# PIC32CX2051BZ62132 device description
Architecture: CORTEX-M4; Family: PIC32CX; Series: PIC32CXBZ62
Registers are 32-bit, read-write, reset 0x0 unless marked. A register's access mark holds for its fields unless they carry their own. Offsets are from the block's base; [hi:lo] are bit positions; 'fields as' and 'values as' point back to an identical list.

## QEI
Instances: QEI 0x44005000
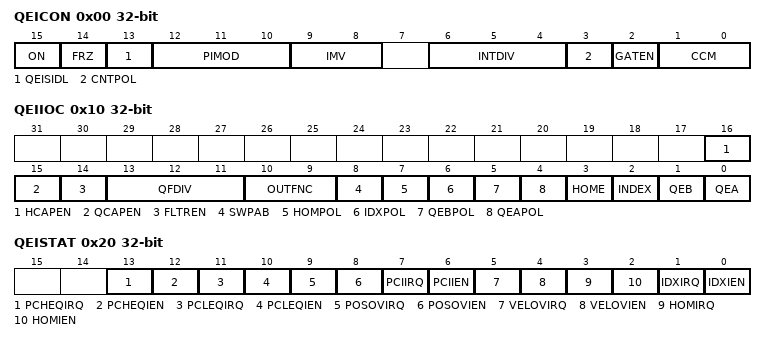
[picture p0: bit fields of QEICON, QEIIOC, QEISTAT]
0x00 QEICON reset not defined — QEI Control Register
  [15] ON — Quadrature Encoder Interface Module Counter Enable bit
    1=ON (Module counters are enabled); 0=OFF (Module counters are disabled)
  [14] FRZ — Quadrature Encoder Interface Freeze debug mode
  [13] QEISIDL — Stop in Idle Mode bit
    1=DISCONT (Discontinue module operation when device enters Idle mode); 0=CONT (Continue module operation in Idle mode)
  [12:10] PIMOD — Position Counter Initialization Mode Select bits
    7=Modulo Count mode for position counter and every index event resets the position counter; 6=Modulo Count mode for position counter; 5=Resets the position counter when the position counter equals QEIICCH register; 4=Second index event after home event initializes position counter with contents of QEIICCHregister; 3=First index event after home event initializes position counter with contents of QEIICCH register; 2=Next index input event initializes the position counter with contents of QEIICCH register; 1=Every Index input event resets the position counter; 0=Index input event does not affect position counter
  [9:8] IMV — Index Match Value bits
    3=B1_A1 (Index match occurs when QEB is 1 and QEA is 1); 2=B1_A0 (Index match occurs when QEB is 1 and QEA is 0); 1=B0_A1 (Index match occurs when QEB is 0 and QEA is 1); 0=B0_A0 (Index match occurs when QEB is 0 and QEA is 0)
  [6:4] INTDIV — Timer Input Clock Prescale Select bits
    7=1:128 prescale value; 6=1:64 prescale value; 5=1:32 prescale value; 4=1:16 prescale value; 3=1_8 (1:8 prescale value); 2=1_4 (1:4 prescale value); 1=1_2 (1:2 prescale value); 0=1:1 prescale value
  [3] CNTPOL — Position and Index Counter/Timer Direction Select bit
    1=NEG (Counter direction is negative unless modified by external Up/Down signal); 0=POS (Counter direction is positive unless modified by external Up/Down signal)
  [2] GATEN — External Count Gate Enable bit
    1=ON (External gate signal controls position counter operation); 0=OFF (External gate signal has no affect on position counter/timer operation)
  [1:0] CCM — Counter Control Mode Selection bits
    3=INT_TMR_EXT_COUNT (Internal timer mode with optional external count enable); 2=EXT_CLOCK_EXT_COUNT (External clock count with optional external count gating); 1=EXT_CLK_EXT_UPDN (External clock count with external Up/Dn direction selection); 0=COUNT_MODE (Quadrature Encoder Interface Count mode (x4 mode))
0x04 QEICONCLR — Bit clear register
0x08 QEICONSET — Bit set register
0x0C QEICONINV — Bit invert register
0x10 QEIIOC reset not defined — QEI I/O Control Register
  [16] HCAPEN — Position Counter Input Capture by Home Event Enable bit
    1=TRIGGERED (HOMEx input event (positive edge) triggers a position capture event); 0=NOT_TRIGGERED (HOMEx input event (positive edge) does not trigger a position capture event)
  [15] QCAPEN — Position Counter Input Capture Enable bit
    1=TRIGGERED (Positive edge detect of Home input triggers position capture function); 0=NOT_TRIGGERED (Home input event (positive edge) does not trigger a capture even)
  [14] FLTREN — QEA/QEB/INDX/HOMEx Digital Filter Enable bit
    1=ON (Input Pin Digital filter is enabled); 0=OFF (Input Pin Digital filter is disabled (bypassed))
  [13:11] QFDIV — QEA/QEB/INDX/HOMEx Digital Input Filter Clock Divide Select bits
    7=1:128 clock divide; 6=1:64 clock divide; 5=1:32 clock divide; 4=1:16 clock divide; 3=1_8 (1:8 clock divide); 2=1_4 (1:4 clock divide); 1=1_2 (1:2 clock divide); 0=1:1 clock divide
  [10:9] OUTFNC — QEI Module Output Function Mode Select bits
    3=EITHER (The position coutner is either case); 2=LESS_THAN (The position counter less than or equal to the range of CMPLH and CMPLL); 1=GREATER_THAN (The position counter greater than or equal to the range of ICCH and ICCL); 0=DISABLE (Output is disabled)
  [8] SWPAB — Swap QEA and QEB Inputs bit
    1=SWAP (QEAx and QEBx are swapped prior to quadrature decoder logic); 0=NORMAL (QEAx and QEBx are not swapped)
  [7] HOMPOL — HOMEx Input Polarity Select bit
    1=INVERT (Input is inverted); 0=NORMAL (Input is not inverted)
  [6] IDXPOL — INDXx Input Polarity Select bit
    values as HOMPOL
  [5] QEBPOL — QEBx Input Polarity Select bit
    values as HOMPOL
  [4] QEAPOL — QEAx Input Polarity Select bit
    values as HOMPOL
  [3] HOME — Status of HOMEx Input Pin after Polarity Control bit
  [2] INDEX — Status of INDXx Input Pin after Polarity Control bit
  [1] QEB — Status of QEBx Input Pin after Polarity Control and SWPAB Pin Swapping bit
    1=Status of QEB input pin after polarity control and SWPAB pin swapping; 0=Status of QEB input pin after polarity control and SWPAB pin swapping
  [0] QEA — Status of QEAx Input Pin after Polarity Control and SWPAB Pin Swapping bit
    1=Status of QEA input pin after polarity control and SWPAB pin swapping; 0=Status of QEA input pin after polarity control and SWPAB pin swapping
0x14 QQEIIOCCLR — Bit clear register
0x18 QEIIOCSET — Bit set register
0x1C QEIIOCINV — Bit invert register
0x20 QEISTAT reset not defined — QEI Status Register
  [13] PCHEQIRQ — Position Counter Greater Than or Equal Compare Status bit
    1=MORE_EQUAL (POSxCNT greater than or equal to QEIICCH); 0=LESS (POSxCNT less than QEIICCH)
  [12] PCHEQIEN — Position Counter Greater Than or Equal Compare Interrupt Enable bit
    1=ON (Interrupt is enabled); 0=OFF (Interrupt is disabled)
  [11] PCLEQIRQ — Position Counter Less Than or Equal Compare Status bit
    1=LESS_EQUAL (POSxCNT less than or equal to QEICMPL); 0=GREATER (POSxCNT greater than QEICMPL)
  [10] PCLEQIEN — Position Counter Less Than or Equal Compare Interrupt Enable bit
    1=ON (Interrupt is enabled); 0=OFF (Interrupt is disabled)
  [9] POSOVIRQ — Position Counter Overflow Status bit
    1=OVERFLOW (Overflow has occurred); 0=NO_OVERFLOW (No overflow has occurred)
  [8] POSOVIEN — Position Counter Overflow Interrupt Enable bit
    1=ON (Interrupt is enabled); 0=OFF (Interrupt is disabled)
  [7] PCIIRQ — Position Counter Initialization Process Complete Status bit
    1=DONE (POSxCNT was reinitialized); 0=NOT_DONE (POSxCNT was not reinitialized)
  [6] PCIIEN — Position Counter Initialization Process Complete Interrupt Enable bit
    1=ON (Interrupt is enabled); 0=OFF (Interrupt is disabled)
  [5] VELOVIRQ — Velocity Counter Overflow Status bit
    1=OVERFLOW (Overflow has occurred); 0=NO_OVERFLOW (No overflow has not occurred)
  [4] VELOVIEN — Velocity Counter Overflow Interrupt Enable bit
    1=ON (Interrupt is enabled); 0=OFF (Interrupt is disabled)
  [3] HOMIRQ — Status Flag for Home Event Status bit
    1=ON (Home event has occurred); 0=OFF (No Home event has occurred)
  [2] HOMIEN — Home Input Event Interrupt Enable bit
    1=ON (Interrupt is enabled); 0=OFF (Interrupt is disabled)
  [1] IDXIRQ — Status Flag for Index Event Status bit
    1=ON (Index event has occurred); 0=OFF (No Index event has occurred)
  [0] IDXIEN — Index Input Event Interrupt Enable bit
    1=ON (Interrupt is enabled); 0=OFF (Interrupt is disabled)
0x24 QEISTATCLR — Bit clear register
0x28 QEISTATSET — Bit set register
0x2C QEISTATINV — Bit invert register
0x30 POSCNT reset not defined — Position Counter Register
  [31:0] POSCNT — Position Counter
0x34 POSCNTCLR — Bit clear register
0x38 POSCNTSET — Bit set register
0x3C POSCNTINV — Bit invert register
0x40 POSHLD reset not defined — Position Count Hold Register
  [31:0] POSHLD — Position Count Hold
0x44 POSHLDCLR — Bit clear register
0x48 POSHLDSET — Bit set register
0x4C POSHLDINV — Bit invert register
0x50 VELCNT reset not defined — Velocity Counter Register
  [31:0] VELCNT — Velocity Counter
0x54 VELCNTCLR — Bit clear register
0x58 VELCNTSET — Bit set register
0x5C VELCNTINV — Bit invert register
0x60 VELHLD reset not defined — Velocity Counter Holding Register
  [31:0] VELHLD — Velocity Cout Hold
0x64 VELHLDCLR — Bit clear register
0x68 VELHLDSET — Bit set register
0x6C VELHLDINV — Bit invert register
0x70 INTTMR reset not defined — Interval Timer Register
  [31:0] INTTMR — Interval Timer
0x74 INTTMRCLR — Bit clear register
0x78 INTTMRSET — Bit set register
0x7C INTTMRINV — Bit invert register
0x80 INTHLD reset not defined — Interval Timer Holding Register
  [31:0] INTHLD — Interval Count Hold
0x84 INTHLDCLR — Bit clear register
0x88 INTHLDSET — Bit set register
0x8C INTHLDINV — Bit invert register
0x90 INDXCNT reset not defined — Index Counter Register
  [31:0] INDXCNT — Index Counter
0x94 INDXCNTCLR — Bit clear register
0x98 INDXCNTSET — Bit set register
0x9C INDXCNTINV — Bit invert register
0xA0 INDXHLD reset not defined — Index Counter Holding Register
  [31:0] INDXHLD — Index Count Hold
0xA4 INDXHLDCLR — Bit clear register
0xA8 INDXHLDSET — Bit set register
0xAC INDXHLDINV — Bit invert register
0xB0 QEIICC reset not defined — QEI Initialize/Capture/Compare Register
  [31:0] QEIICC — 32-bit Initialize/Capture/Compare High bits
0xB4 QEIICCCLR — Bit clear register
0xB8 QEIICCSET — Bit set register
0xBC QEIICCINV — Bit invert register
0xC0 QEICMPL reset not defined — Capture Low Register
  [31:0] QEICMPL — 32-bit Compare Low Value bits
0xC4 QEICMPLCLR — Bit clear register
0xC8 QEICMPLSET — Bit set register
0xCC QEICMPLINV — Bit invert register
